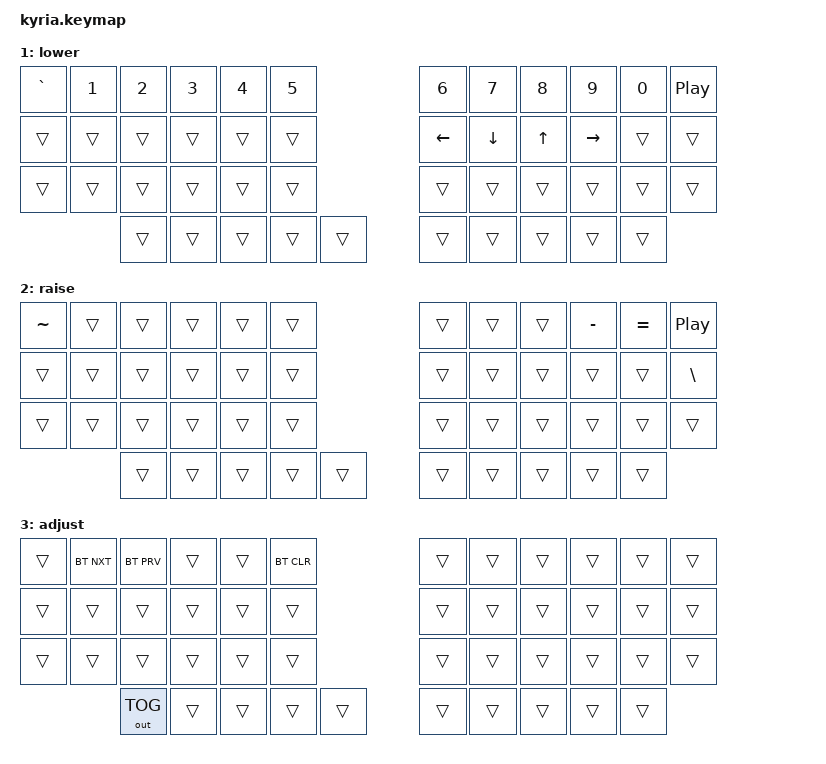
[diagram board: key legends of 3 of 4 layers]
#include <behaviors.dtsi>
#include <dt-bindings/zmk/keys.h>
#include <dt-bindings/zmk/bt.h>
#include <dt-bindings/zmk/outputs.h>

#define LOWR 1
#define RAIS 2
#define ADJT 3

/ {
	keymap {
		compatible = "zmk,keymap";

		default_layer {
// ---------------------------------------------------------------------------------------------------------------------------------
// |  ESC  |  Q  |  W  |  E   |  R   |  T   |                                          |  Y   |  U    |  I    |  O   |   P   |   \  |
// |  TAB  |  A  |  S  |  D   |  F   |  G   |                                          |  H   |  J    |  K    |  L   |   ;   |   '  |
// | SHIFT |  Z  |  X  |  C   |  V   |  B   | L SHIFT | L SHIFT |  | L SHIFT | L SHIFT |  N   |  M    |  ,    |  .   |   /   | CTRL |
//                     | GUI  | DEL  | RET  |  SPACE  |   ESC   |  |   RET   |  SPACE  | TAB  | BSPC  | R-ALT |
			bindings = <
	&lt ADJT ESC &kp Q &kp W &kp E &kp R &kp T                                                &kp Y &kp U  &kp I     &kp O   &kp P    &kp C_MUTE
	&kp TAB   &kp A &kp S &kp D &kp F &kp G                                                &kp H &kp J  &kp K     &kp L   &kp SEMI &kp SQT
	&kp LSHFT &trans &kp Z &kp X &kp C &kp V &kp LBKT &trans           &trans &kp RBKT     &kp B &kp N  &kp M    &kp COMMA &kp DOT &kp FSLH
	                 &kp LCTRL &kp LALT &mo LOWR &kp LGUI &kp BSPC     &kp SPACE  &kp ENTER &mo RAIS &trans &trans
			>;

			sensor-bindings = <&inc_dec_kp C_VOL_UP C_VOL_DN &inc_dec_kp C_VOL_UP C_VOL_DN>;
		};

		lower {
			bindings = <
	&kp GRAVE &kp N1 &kp N2 &kp N3 &kp N4 &kp N5                                           &kp N6  &kp N7  &kp N8     &kp N9   &kp N0    &kp C_PLAY_PAUSE
	&trans    &trans &trans &trans &trans &trans                                           &kp LEFT &kp DOWN &kp UP &kp RIGHT  &trans    &trans
	&trans    &trans &trans &trans &trans &trans                                           &trans  &trans  &trans     &trans   &trans    &trans
	                 &trans &trans &trans &trans &trans                             &trans &trans  &trans  &trans     &trans
			>;

			sensor-bindings = <&inc_dec_kp C_NEXT C_PREV &inc_dec_kp C_NEXT C_PREV>;
		};
		raise {
			bindings = <
	&kp TILDE &trans &trans &trans &trans &trans                                           &trans  &trans  &trans  &kp MINUS &kp EQUAL &kp C_PLAY_PAUSE
	&trans    &trans &trans &trans &trans &trans                                           &trans  &trans  &trans  &trans  &trans  &kp BSLH
	&trans    &trans &trans &trans &trans &trans                                           &trans  &trans  &trans  &trans  &trans  &trans
	                 &trans &trans &trans &trans &trans                             &trans &trans  &trans  &trans  &trans
			>;

			sensor-bindings = <&inc_dec_kp C_NEXT C_PREV &inc_dec_kp C_NEXT C_PREV>;
		};

		adjust {
			bindings = <
	&trans &bt BT_NXT &bt BT_PRV &trans &trans &bt BT_CLR                               &trans  &trans  &trans  &trans  &trans  &trans
	&trans &trans &trans &trans &trans &trans                                           &trans  &trans  &trans  &trans  &trans  &trans
	&trans &trans &trans &trans &trans &trans                                           &trans  &trans  &trans  &trans  &trans  &trans
	              &out OUT_TOG &trans &trans &trans &trans                             &trans &trans  &trans  &trans  &trans
			>;

			sensor-bindings = <&inc_dec_kp C_NEXT C_PREV &inc_dec_kp C_NEXT C_PREV>;
		};
	};
};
